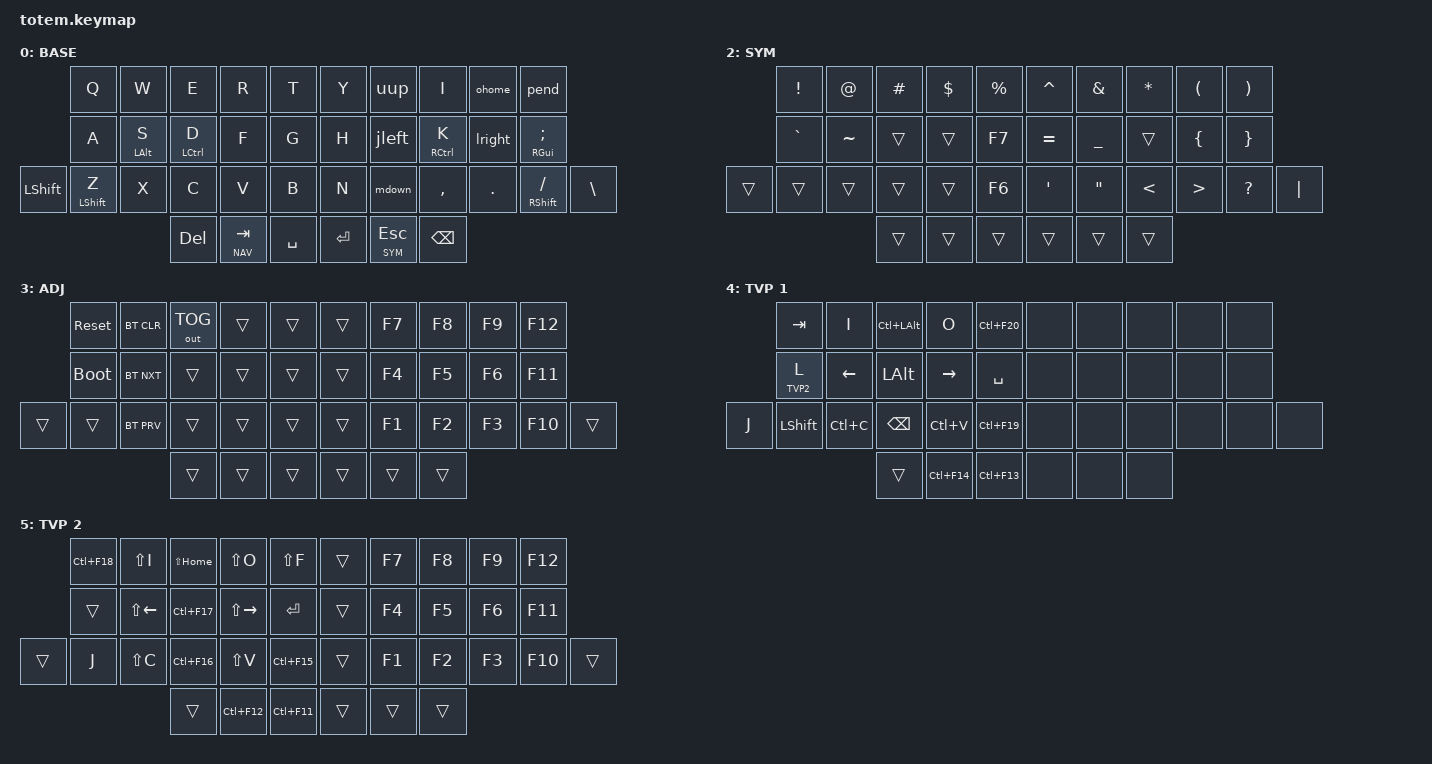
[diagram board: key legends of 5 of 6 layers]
//
//                                                        ▀▀▀▀▀     ▀▀▀▀▀          ▀▀█▀▀
//                                                        ▄▀▀▀▄  ▄  ▄▀▀▀▄  ▄  ▄▀▀▀▄  █  ▄▀▀▀▄
//                                                        █   █  █  █   █  █  █   █  █  █   █
//                                                         ▀▀▀   █   ▀▀▀   █   ▀▀▀   ▀   ▀▀▀
//                                                               █      ▄▄▄█▄▄▄    █   █  
//                                                               ▀      █  █  █     █▄█
//                                                             ▀▀▀▀▀    █  █  █      ▀
//                                                                      ▀  ▀  ▀
//
// ▄▄▄▄▄▄▄▄▄▄▄▄▄▄▄▄▄▄▄▄▄▄▄▄▄▄▄▄▄▄▄▄▄▄▄▄▄▄▄▄▄▄▄▄▄▄▄▄▄▄▄▄▄▄▄▄▄▄▄▄▄▄▄▄▄▄▄▄▄▄▄▄▄▄▄▄▄▄▄▄▄▄▄▄▄▄▄▄▄▄▄▄▄▄▄▄▄▄▄▄▄▄▄▄▄▄▄▄▄▄▄▄▄▄▄▄▄▄▄▄▄▄▄▄▄▄▄▄▄▄▄▄▄▄▄▄▄▄▄▄▄▄▄▄▄▄▄▄▄
       

#include <behaviors.dtsi>
#include <dt-bindings/zmk/keys.h>
#include <dt-bindings/zmk/bt.h>
#include <dt-bindings/zmk/outputs.h>

#define BASE 0
#define NAV  1
#define SYM  2
#define ADJ  3
#define TVP1 4
#define TVP2 5

&mt {
  quick-tap-ms = <170>;
  global-quick-tap;
  flavor = "tap-preferred";
  tapping-term-ms = <200>;
};

/ {
    behaviors {
        jleft: j_left {
            compatible = "zmk,behavior-mod-morph";
            #binding-cells = <0>;
            bindings = <&kp J>, <&kp LEFT>;
            mods = <MOD_RCTL>;
        };

        lright: l_right {
            compatible = "zmk,behavior-mod-morph";
            #binding-cells = <0>;
            bindings = <&kp L>, <&kp RIGHT>;
            mods = <MOD_RCTL>;
        };

        uup: u_up {
            compatible = "zmk,behavior-mod-morph";
            #binding-cells = <0>;
            bindings = <&kp U>, <&kp UP>;
            mods = <MOD_RCTL>;
        };

        mdown: m_down {
            compatible = "zmk,behavior-mod-morph";
            #binding-cells = <0>;
            bindings = <&kp M>, <&kp DOWN>;
            mods = <MOD_RCTL>;
        };

        ohome: o_home {
            compatible = "zmk,behavior-mod-morph";
            #binding-cells = <0>;
            bindings = <&kp O>, <&kp HOME>;
            mods = <MOD_RCTL>;
        };

        pend: p_end {
            compatible = "zmk,behavior-mod-morph";
            #binding-cells = <0>;
            bindings = <&kp P>, <&kp END>;
            mods = <MOD_RCTL>;
        };
    };

     combos {
            compatible = "zmk,combos";
            combo_esc {
                timeout-ms = <50>;
                key-positions = <0 1>;
                bindings = <&kp ESC>;
            };
            combo_tvp {
                timeout-ms = <100>;
                key-positions = <11 12 13>;
                bindings = <&tog TVP1>;
            };
    };

    macros {
        gif: gif {
            label = "giphy";
            compatible = "zmk,behavior-macro";
            #binding-cells = <0>;
            bindings
                = <&macro_press &kp LSHFT>
                , <&macro_tap &kp N2>
                , <&macro_release &kp LSHFT>
                , <&macro_tap &kp G &kp I &kp F>
                ;
        };
    };

        keymap {
                compatible = "zmk,keymap";
// ▄▄▄▄▄▄▄▄▄▄▄▄▄▄▄▄▄▄▄▄▄▄▄▄▄▄▄▄▄▄▄▄▄▄▄▄▄▄▄▄▄▄▄▄▄▄▄▄▄▄▄▄▄▄▄▄▄▄▄▄▄▄▄▄▄▄▄▄▄▄▄▄▄▄▄▄▄▄▄▄▄▄▄▄▄▄▄▄▄▄▄▄▄▄▄▄▄▄▄▄▄▄▄▄▄▄▄▄▄▄▄▄▄▄▄▄▄▄▄▄▄▄▄▄▄▄▄▄▄▄▄▄▄▄▄▄▄▄▄▄▄▄▄▄▄▄▄▄▄

                base_layer {
// ┏━━━━━━━━━━━━━━━━━━━━━━━━━━━━━━━━━━━━━━━┓
label= "BASE"                              ;
// ┗━━━━━━━━━━━━━━━━━━━━━━━━━━━━━━━━━━━━━━━┛
//             ┏━━━━━━━━━━━┳━━━━━━━━━━━┳━━━━━━━━━━━┳━━━━━━━━━━━┳━━━━━━━━━━━┓   ┏━━━━━━━━━━━┳━━━━━━━━━━━┳━━━━━━━━━━━┳━━━━━━━━━━━┳━━━━━━━━━━━┓
//             ┃     Q     ┃     W     ┃     E     ┃     R     ┃     T     ┃   ┃     Y     ┃     U     ┃     I     ┃     O     ┃     P     ┃
//             ┣━━━━━━━━━━━╋━━━━━━━━━━━╋━━━━━━━━━━━╋━━━━━━━━━━━╋━━━━━━━━━━━┫   ┣━━━━━━━━━━━╋━━━━━━━━━━━╋━━━━━━━━━━━╋━━━━━━━━━━━╋━━━━━━━━━━━┫
//             ┃     A     ┃     S     ┃     D     ┃     F     ┃     G     ┃   ┃     H     ┃     J     ┃     K     ┃     L     ┃     ;     ┃
// ┏━━━━━━━━━━━╋━━━━━━━━━━━╋━━━━━━━━━━━╋━━━━━━━━━━━╋━━━━━━━━━━━╋━━━━━━━━━━━┫   ┣━━━━━━━━━━━╋━━━━━━━━━━━╋━━━━━━━━━━━╋━━━━━━━━━━━╋━━━━━━━━━━━╋━━━━━━━━━━━┓
// ┃   SHIFT   ┃     Z     ┃     X     ┃     C     ┃     V     ┃     B     ┃   ┃     N     ┃     M     ┃     ,     ┃     .     ┃     /     ┃     \     ┃
// ┗━━━━━━━━━━━┻━━━━━━━━━━━┻━━━━━━━━━━━╋━━━━━━━━━━━╋━━━━━━━━━━━╋━━━━━━━━━━━┫   ┣━━━━━━━━━━━╋━━━━━━━━━━━╋━━━━━━━━━━━╋━━━━━━━━━━━┻━━━━━━━━━━━┻━━━━━━━━━━━┛
//                                     ┃    DEL    ┃    TAB    ┃    SPC    ┃   ┃   ENTER   ┃           ┃   BSPC    ┃
//                                     ┗━━━━━━━━━━━┻━━━━━━━━━━━┻━━━━━━━━━━━┛   ┗━━━━━━━━━━━┻━━━━━━━━━━━┻━━━━━━━━━━━┛
 bindings = <
// ╷           ╷           ╷           ╷           ╷           ╷           ╷   ╷           ╷           ╷           ╷           ╷           ╷           ╷

                &kp Q       &kp W       &kp E       &kp R       &kp T           &kp Y       &uup        &kp I          &ohome       &pend
                &kp A       &mt LALT S  &mt LCTRL D &kp F       &kp G           &kp H       &jleft      &mt RCTRL K    &lright      &mt RGUI SEMI
    &kp LSHFT   &mt LSHFT Z &kp X       &kp C       &kp V       &kp B           &kp N       &mdown      &kp COMMA      &kp DOT      &mt RSHFT FSLH    &kp BSLH
                                        &kp DEL   &lt NAV TAB   &kp SPACE       &kp RET   &lt SYM ESC   &kp BSPC
                        >;
                };

// ▄▄▄▄▄▄▄▄▄▄▄▄▄▄▄▄▄▄▄▄▄▄▄▄▄▄▄▄▄▄▄▄▄▄▄▄▄▄▄▄▄▄▄▄▄▄▄▄▄▄▄▄▄▄▄▄▄▄▄▄▄▄▄▄▄▄▄▄▄▄▄▄▄▄▄▄▄▄▄▄▄▄▄▄▄▄▄▄▄▄▄▄▄▄▄▄▄▄▄▄▄▄▄▄▄▄▄▄▄▄▄▄▄▄▄▄▄▄▄▄▄▄▄▄▄▄▄▄▄▄▄▄▄▄▄▄▄▄▄▄▄▄▄▄▄▄▄▄▄


                nav_layer {
// ┏━━━━━━━━━━━━━━━━━━━━━━━━━━━━━━━━━━━━━━━┓
label= "NAVI"                              ;
// ┗━━━━━━━━━━━━━━━━━━━━━━━━━━━━━━━━━━━━━━━┛
//             ┏━━━━━━━━━━━┳━━━━━━━━━━━┳━━━━━━━━━━━┳━━━━━━━━━━━┳━━━━━━━━━━━┓   ┏━━━━━━━━━━━┳━━━━━━━━━━━┳━━━━━━━━━━━┳━━━━━━━━━━━┳━━━━━━━━━━━┓
//             ┃     1     ┃     2     ┃     3     ┃     4     ┃     5     ┃   ┃     6     ┃     7     ┃     8     ┃     9     ┃     0     ┃
//             ┣━━━━━━━━━━━╋━━━━━━━━━━━╋━━━━━━━━━━━╋━━━━━━━━━━━╋━━━━━━━━━━━┫   ┣━━━━━━━━━━━╋━━━━━━━━━━━╋━━━━━━━━━━━╋━━━━━━━━━━━╋━━━━━━━━━━━┫
//             ┃    F8     ┃    F9     ┃    F10    ┃    F11    ┃    F12    ┃   ┃     +     ┃     -     ┃   PGUP    ┃     [     ┃     ]     ┃
// ┏━━━━━━━━━━━╋━━━━━━━━━━━╋━━━━━━━━━━━╋━━━━━━━━━━━╋━━━━━━━━━━━╋━━━━━━━━━━━┫   ┣━━━━━━━━━━━╋━━━━━━━━━━━╋━━━━━━━━━━━╋━━━━━━━━━━━╋━━━━━━━━━━━╋━━━━━━━━━━━┓
// ┃           ┃    F1     ┃    F2     ┃    F3     ┃    F4     ┃    F5     ┃   ┃           ┃           ┃   PGDN    ┃           ┃           ┃           ┃
// ┗━━━━━━━━━━━┻━━━━━━━━━━━┻━━━━━━━━━━━╋━━━━━━━━━━━╋━━━━━━━━━━━╋━━━━━━━━━━━┫   ┣━━━━━━━━━━━╋━━━━━━━━━━━╋━━━━━━━━━━━╋━━━━━━━━━━━┻━━━━━━━━━━━┻━━━━━━━━━━━┛
//                                     ┃           ┃    TAB    ┃    SPC    ┃   ┃    DEL    ┃           ┃           ┃
//                                     ┗━━━━━━━━━━━┻━━━━━━━━━━━┻━━━━━━━━━━━┛   ┗━━━━━━━━━━━┻━━━━━━━━━━━┻━━━━━━━━━━━┛
 bindings = <
// ╷           ╷           ╷           ╷           ╷           ╷           ╷   ╷           ╷           ╷           ╷           ╷           ╷           ╷

                &kp N1      &kp N2       &kp N3     &kp N4      &kp N5          &kp N6      &kp N7      &kp N8      &kp N9      &kp N0
                &kp F8      &kp F9      &kp F10     &kp F11     &kp F12         &kp PLUS    &kp MINUS   &kp PG_UP   &kp LBKT    &kp RBKT
    &trans      &kp F1      &kp F2      &kp F3      &kp F4      &kp F5          &trans      &trans      &kp PG_DN   &trans      &trans      &trans      
                                        &lt ADJ DEL   &trans    &trans          &kp DEL     &trans      
                        >;
                };

// ▄▄▄▄▄▄▄▄▄▄▄▄▄▄▄▄▄▄▄▄▄▄▄▄▄▄▄▄▄▄▄▄▄▄▄▄▄▄▄▄▄▄▄▄▄▄▄▄▄▄▄▄▄▄▄▄▄▄▄▄▄▄▄▄▄▄▄▄▄▄▄▄▄▄▄▄▄▄▄▄▄▄▄▄▄▄▄▄▄▄▄▄▄▄▄▄▄▄▄▄▄▄▄▄▄▄▄▄▄▄▄▄▄▄▄▄▄▄▄▄▄▄▄▄▄▄▄▄▄▄▄▄▄▄▄▄▄▄▄▄▄▄▄▄▄▄▄▄▄


                sim_layer {
// ┏━━━━━━━━━━━━━━━━━━━━━━━━━━━━━━━━━━━━━━━┓
label= "SYM"                               ;
// ┗━━━━━━━━━━━━━━━━━━━━━━━━━━━━━━━━━━━━━━━┛
//             ┏━━━━━━━━━━━┳━━━━━━━━━━━┳━━━━━━━━━━━┳━━━━━━━━━━━┳━━━━━━━━━━━┓   ┏━━━━━━━━━━━┳━━━━━━━━━━━┳━━━━━━━━━━━┳━━━━━━━━━━━┳━━━━━━━━━━━┓
//             ┃     !     ┃     @     ┃     #     ┃     $     ┃     %     ┃   ┃     ˆ     ┃     &     ┃     *     ┃     (     ┃     )     ┃
//             ┣━━━━━━━━━━━╋━━━━━━━━━━━╋━━━━━━━━━━━╋━━━━━━━━━━━╋━━━━━━━━━━━┫   ┣━━━━━━━━━━━╋━━━━━━━━━━━╋━━━━━━━━━━━╋━━━━━━━━━━━╋━━━━━━━━━━━┫
//             ┃     `     ┃     ~     ┃           ┃           ┃    F7     ┃   ┃     =     ┃     _     ┃           ┃     {     ┃     }     ┃
// ┏━━━━━━━━━━━╋━━━━━━━━━━━╋━━━━━━━━━━━╋━━━━━━━━━━━╋━━━━━━━━━━━╋━━━━━━━━━━━┫   ┣━━━━━━━━━━━╋━━━━━━━━━━━╋━━━━━━━━━━━╋━━━━━━━━━━━╋━━━━━━━━━━━╋━━━━━━━━━━━┓
// ┃           ┃           ┃           ┃           ┃           ┃    F6     ┃   ┃     '     ┃     "     ┃     <     ┃     >     ┃     ?     ┃     |     ┃
// ┗━━━━━━━━━━━┻━━━━━━━━━━━┻━━━━━━━━━━━╋━━━━━━━━━━━╋━━━━━━━━━━━╋━━━━━━━━━━━┫   ┣━━━━━━━━━━━╋━━━━━━━━━━━╋━━━━━━━━━━━╋━━━━━━━━━━━┻━━━━━━━━━━━┻━━━━━━━━━━━┛
//                                     ┃           ┃           ┃           ┃   ┃           ┃           ┃           ┃
//                                     ┗━━━━━━━━━━━┻━━━━━━━━━━━┻━━━━━━━━━━━┛   ┗━━━━━━━━━━━┻━━━━━━━━━━━┻━━━━━━━━━━━┛
 bindings = <
// ╷           ╷           ╷           ╷           ╷           ╷           ╷   ╷           ╷           ╷           ╷           ╷           ╷           ╷

                &kp EXCL    &kp AT      &kp HASH    &kp DLLR    &kp PRCNT       &kp CARET   &kp AMPS        &kp STAR   &kp LPAR    &kp RPAR        
                &kp GRAVE   &kp TILDE   &trans      &trans      &kp F7          &kp EQUAL   &kp UNDERSCORE  &trans     &kp LBRC    &kp RBRC            
    &trans      &trans      &trans      &trans      &trans      &kp F6          &kp SQT     &kp DQT         &kp LT     &kp GT      &kp QMARK   &kp PIPE         
                                        &trans      &trans      &trans          &trans      &trans          &trans      
                        >;
                };

// ▄▄▄▄▄▄▄▄▄▄▄▄▄▄▄▄▄▄▄▄▄▄▄▄▄▄▄▄▄▄▄▄▄▄▄▄▄▄▄▄▄▄▄▄▄▄▄▄▄▄▄▄▄▄▄▄▄▄▄▄▄▄▄▄▄▄▄▄▄▄▄▄▄▄▄▄▄▄▄▄▄▄▄▄▄▄▄▄▄▄▄▄▄▄▄▄▄▄▄▄▄▄▄▄▄▄▄▄▄▄▄▄▄▄▄▄▄▄▄▄▄▄▄▄▄▄▄▄▄▄▄▄▄▄▄▄▄▄▄▄▄▄▄▄▄▄▄▄▄


                adjust_layer {
// ┏━━━━━━━━━━━━━━━━━━━━━━━━━━━━━━━━━━━━━━━┓
label= "ADJ"                               ;
// ┗━━━━━━━━━━━━━━━━━━━━━━━━━━━━━━━━━━━━━━━┛
//             ┏━━━━━━━━━━━┳━━━━━━━━━━━┳━━━━━━━━━━━┳━━━━━━━━━━━┳━━━━━━━━━━━┓   ┏━━━━━━━━━━━┳━━━━━━━━━━━┳━━━━━━━━━━━┳━━━━━━━━━━━┳━━━━━━━━━━━┓
//             ┃   RESET   ┃ BT CLEAR  ┃  OUT TOG  ┃           ┃           ┃   ┃           ┃    F7     ┃    F8     ┃    F9     ┃    F12    ┃
//             ┣━━━━━━━━━━━╋━━━━━━━━━━━╋━━━━━━━━━━━╋━━━━━━━━━━━╋━━━━━━━━━━━┫   ┣━━━━━━━━━━━╋━━━━━━━━━━━╋━━━━━━━━━━━╋━━━━━━━━━━━╋━━━━━━━━━━━┫
//             ┃ BOOTLOAD  ┃ BT NEXT   ┃           ┃           ┃           ┃   ┃           ┃    F4     ┃    F5     ┃    F6     ┃    F11    ┃
// ┏━━━━━━━━━━━╋━━━━━━━━━━━╋━━━━━━━━━━━╋━━━━━━━━━━━╋━━━━━━━━━━━╋━━━━━━━━━━━┫   ┣━━━━━━━━━━━╋━━━━━━━━━━━╋━━━━━━━━━━━╋━━━━━━━━━━━╋━━━━━━━━━━━╋━━━━━━━━━━━┓
// ┃           ┃           ┃ BT PREV   ┃           ┃           ┃           ┃   ┃           ┃    F1     ┃    F2     ┃    F3     ┃    F10    ┃           ┃
// ┗━━━━━━━━━━━┻━━━━━━━━━━━┻━━━━━━━━━━━╋━━━━━━━━━━━╋━━━━━━━━━━━╋━━━━━━━━━━━┫   ┣━━━━━━━━━━━╋━━━━━━━━━━━╋━━━━━━━━━━━╋━━━━━━━━━━━┻━━━━━━━━━━━┻━━━━━━━━━━━┛
//                                     ┃           ┃           ┃           ┃   ┃           ┃           ┃           ┃
//                                     ┗━━━━━━━━━━━┻━━━━━━━━━━━┻━━━━━━━━━━━┛   ┗━━━━━━━━━━━┻━━━━━━━━━━━┻━━━━━━━━━━━┛
 bindings = <
// ╷           ╷           ╷           ╷           ╷           ╷           ╷   ╷           ╷           ╷           ╷           ╷           ╷           ╷

                &sys_reset  &bt BT_CLR &out OUT_TOG &trans      &trans          &trans      &kp F7      &kp F8      &kp F9      &kp F12
                &bootloader &bt BT_NXT  &trans      &trans      &trans          &trans      &kp F4      &kp F5      &kp F6      &kp F11  
    &trans      &trans      &bt BT_PRV  &trans      &trans      &trans          &trans      &kp F1      &kp F2      &kp F3      &kp F10     &trans         
                                        &trans      &trans      &trans          &trans      &trans      &trans      
                        >;
                };

// ▄▄▄▄▄▄▄▄▄▄▄▄▄▄▄▄▄▄▄▄▄▄▄▄▄▄▄▄▄▄▄▄▄▄▄▄▄▄▄▄▄▄▄▄▄▄▄▄▄▄▄▄▄▄▄▄▄▄▄▄▄▄▄▄▄▄▄▄▄▄▄▄▄▄▄▄▄▄▄▄▄▄▄▄▄▄▄▄▄▄▄▄▄▄▄▄▄▄▄▄▄▄▄▄▄▄▄▄▄▄▄▄▄▄▄▄▄▄▄▄▄▄▄▄▄▄▄▄▄▄▄▄▄▄▄▄▄▄▄▄▄▄▄▄▄▄▄▄▄


                tvp1_layer {
// ┏━━━━━━━━━━━━━━━━━━━━━━━━━━━━━━━━━━━━━━━┓
label= "TVP 1"                             ;
// ┗━━━━━━━━━━━━━━━━━━━━━━━━━━━━━━━━━━━━━━━┛
//             ┏━━━━━━━━━━━┳━━━━━━━━━━━┳━━━━━━━━━━━┳━━━━━━━━━━━┳━━━━━━━━━━━┓   ┏━━━━━━━━━━━┳━━━━━━━━━━━┳━━━━━━━━━━━┳━━━━━━━━━━━┳━━━━━━━━━━━┓
//             ┃ NEXT FILE ┃ MARK IN   ┃ ROTATE    ┃ MARK OUT  ┃ SHOW SNAP ┃   ┃           ┃           ┃           ┃           ┃           ┃
//             ┣━━━━━━━━━━━╋━━━━━━━━━━━╋━━━━━━━━━━━╋━━━━━━━━━━━╋━━━━━━━━━━━┫   ┣━━━━━━━━━━━╋━━━━━━━━━━━╋━━━━━━━━━━━╋━━━━━━━━━━━╋━━━━━━━━━━━┫
//             ┃ TVP II    ┃ LEFT      ┃ PAN       ┃ RIGHT     ┃ PLAY/FLIP ┃   ┃           ┃           ┃           ┃           ┃           ┃
// ┏━━━━━━━━━━━╋━━━━━━━━━━━╋━━━━━━━━━━━╋━━━━━━━━━━━╋━━━━━━━━━━━╋━━━━━━━━━━━┫   ┣━━━━━━━━━━━╋━━━━━━━━━━━╋━━━━━━━━━━━╋━━━━━━━━━━━╋━━━━━━━━━━━╋━━━━━━━━━━━┓
// ┃ FULLSCR   ┃ SHIFT     ┃ COPY      ┃ DELETE    ┃ PASTE     ┃ IMG MARK  ┃   ┃           ┃           ┃           ┃           ┃           ┃           ┃
// ┗━━━━━━━━━━━┻━━━━━━━━━━━┻━━━━━━━━━━━╋━━━━━━━━━━━╋━━━━━━━━━━━╋━━━━━━━━━━━┫   ┣━━━━━━━━━━━╋━━━━━━━━━━━╋━━━━━━━━━━━╋━━━━━━━━━━━┻━━━━━━━━━━━┻━━━━━━━━━━━┛
//                                     ┃           ┃ UNDO/SAVE ┃  SEL/MOV  ┃   ┃           ┃           ┃           ┃
//                                     ┗━━━━━━━━━━━┻━━━━━━━━━━━┻━━━━━━━━━━━┛   ┗━━━━━━━━━━━┻━━━━━━━━━━━┻━━━━━━━━━━━┛
 bindings = <
// ╷           ╷           ╷           ╷           ╷           ╷           ╷   ╷           ╷           ╷           ╷           ╷           ╷           ╷

                &kp TAB     &kp I       &kp LC(LALT) &kp O      &kp LC(F20)     &none       &none       &none       &none       &none
                &lt TVP2 L  &kp LEFT    &kp LALT    &kp RIGHT   &kp SPACE       &none       &none       &none       &none       &none
    &kp J       &kp LSHFT   &kp LC(C)   &kp BSPC    &kp LC(V)   &kp LC(F19)     &none       &none       &none       &none       &none       &none        
                                        &trans      &kp LC(F14) &kp LC(F13)     &none       &none       &none    
                        >;
                };

// ▄▄▄▄▄▄▄▄▄▄▄▄▄▄▄▄▄▄▄▄▄▄▄▄▄▄▄▄▄▄▄▄▄▄▄▄▄▄▄▄▄▄▄▄▄▄▄▄▄▄▄▄▄▄▄▄▄▄▄▄▄▄▄▄▄▄▄▄▄▄▄▄▄▄▄▄▄▄▄▄▄▄▄▄▄▄▄▄▄▄▄▄▄▄▄▄▄▄▄▄▄▄▄▄▄▄▄▄▄▄▄▄▄▄▄▄▄▄▄▄▄▄▄▄▄▄▄▄▄▄▄▄▄▄▄▄▄▄▄▄▄▄▄▄▄▄▄▄▄


                tvp2_layer {
// ┏━━━━━━━━━━━━━━━━━━━━━━━━━━━━━━━━━━━━━━━┓
label= "TVP 2"                             ;
// ┗━━━━━━━━━━━━━━━━━━━━━━━━━━━━━━━━━━━━━━━┛
//             ┏━━━━━━━━━━━┳━━━━━━━━━━━┳━━━━━━━━━━━┳━━━━━━━━━━━┳━━━━━━━━━━━┓   ┏━━━━━━━━━━━┳━━━━━━━━━━━┳━━━━━━━━━━━┳━━━━━━━━━━━┳━━━━━━━━━━━┓
//             ┃ SOLO      ┃ TOGGLE IN ┃ RESET ROT ┃ TOGGLE OUT┃ TAKE SNAP ┃   ┃           ┃           ┃           ┃           ┃           ┃
//             ┣━━━━━━━━━━━╋━━━━━━━━━━━╋━━━━━━━━━━━╋━━━━━━━━━━━╋━━━━━━━━━━━┫   ┣━━━━━━━━━━━╋━━━━━━━━━━━╋━━━━━━━━━━━╋━━━━━━━━━━━╋━━━━━━━━━━━┫
//             ┃ ---       ┃ LAST KEY  ┃ NEW KEY   ┃ NEXT KEY  ┃ ENTER     ┃   ┃           ┃           ┃           ┃           ┃           ┃
// ┏━━━━━━━━━━━╋━━━━━━━━━━━╋━━━━━━━━━━━╋━━━━━━━━━━━╋━━━━━━━━━━━╋━━━━━━━━━━━┫   ┣━━━━━━━━━━━╋━━━━━━━━━━━╋━━━━━━━━━━━╋━━━━━━━━━━━╋━━━━━━━━━━━╋━━━━━━━━━━━┓
// ┃           ┃ FULLSCR   ┃ CPY2BRUSH ┃ DEL HEAD  ┃ PSTinPLACE┃ BOOK MARK ┃   ┃           ┃           ┃           ┃           ┃           ┃           ┃
// ┗━━━━━━━━━━━┻━━━━━━━━━━━┻━━━━━━━━━━━╋━━━━━━━━━━━╋━━━━━━━━━━━╋━━━━━━━━━━━┫   ┣━━━━━━━━━━━╋━━━━━━━━━━━╋━━━━━━━━━━━╋━━━━━━━━━━━┻━━━━━━━━━━━┻━━━━━━━━━━━┛
//                                     ┃           ┃ REDO/SAV1 ┃TRANS/WARP ┃   ┃           ┃           ┃           ┃
//                                     ┗━━━━━━━━━━━┻━━━━━━━━━━━┻━━━━━━━━━━━┛   ┗━━━━━━━━━━━┻━━━━━━━━━━━┻━━━━━━━━━━━┛
 bindings = <
// ╷           ╷           ╷           ╷           ╷           ╷           ╷   ╷           ╷           ╷           ╷           ╷           ╷           ╷

                &kp LC(F18) &kp LS(I)  &kp LS(HOME) &kp LS(O)   &kp LS(F)       &trans      &kp F7      &kp F8      &kp F9      &kp F12
                &trans      &kp LS(LEFT) &kp LC(F17) &kp LS(RIGHT) &kp RET      &trans      &kp F4      &kp F5      &kp F6      &kp F11  
    &trans      &kp J       &kp LS(C)   &kp LC(F16) &kp LS(V)   &kp LC(F15)     &trans      &kp F1      &kp F2      &kp F3      &kp F10     &trans         
                                        &trans      &kp LC(F12) &kp LC(F11)     &trans      &trans      &trans      
                        >;
                };
        };
};
